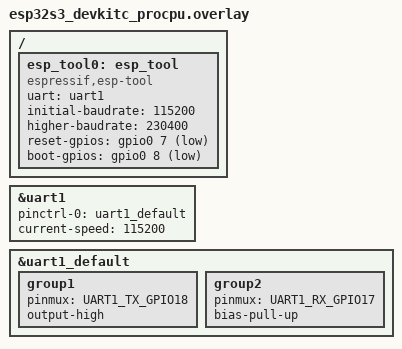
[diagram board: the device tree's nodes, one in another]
/
{
	esp_tool0: esp_tool {
		compatible = "espressif,esp-tool";
		uart = <&uart1>;
		initial-baudrate = <115200>;
		higher-baudrate = <230400>;
		reset-gpios = <&gpio0 7 (GPIO_ACTIVE_LOW | GPIO_PULL_UP)>;
		boot-gpios = <&gpio0 8 (GPIO_ACTIVE_LOW | GPIO_PULL_UP)>;
	};
};

&uart1 {
	pinctrl-0 = <&uart1_default>;
	pinctrl-names = "default";
	current-speed = <115200>;
	status = "okay";
};

&esp_tool0 {
	status = "okay";
};

&uart1_default {
	group1 {
		pinmux = <UART1_TX_GPIO18>;
		output-high;
	};

	group2 {
		pinmux = <UART1_RX_GPIO17>;
		bias-pull-up;
	};
};
